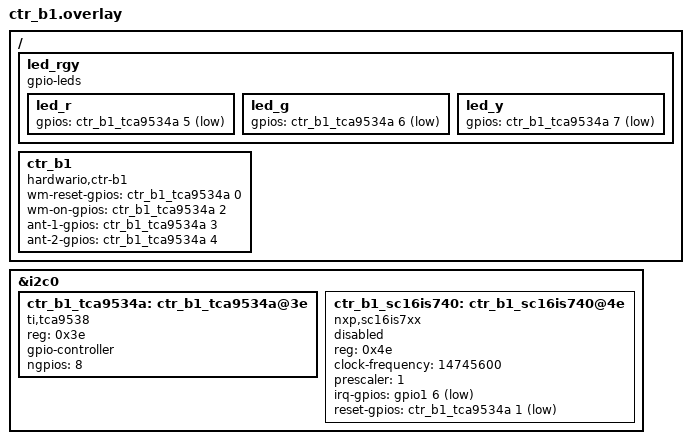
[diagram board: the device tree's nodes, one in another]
/*
 * Copyright (c) 2023 HARDWARIO a.s.
 *
 * SPDX-License-Identifier: LicenseRef-HARDWARIO-5-Clause
 */

/ {
	led_rgy {
		compatible = "gpio-leds";

		led_r: led_r {
			gpios = <&ctr_b1_tca9534a 5 GPIO_ACTIVE_LOW>;
		};

		led_g: led_g {
			gpios = <&ctr_b1_tca9534a 6 GPIO_ACTIVE_LOW>;
		};

		led_y: led_y {
			gpios = <&ctr_b1_tca9534a 7 GPIO_ACTIVE_LOW>;
		};
	};

	ctr_b1: ctr_b1 {
		compatible = "hardwario,ctr-b1";
		status = "okay";
		wm-reset-gpios = <&ctr_b1_tca9534a 0 GPIO_ACTIVE_HIGH>;
		wm-on-gpios = <&ctr_b1_tca9534a 2 GPIO_ACTIVE_HIGH>;
		ant-1-gpios = <&ctr_b1_tca9534a 3 GPIO_ACTIVE_HIGH>;
		ant-2-gpios = <&ctr_b1_tca9534a 4 GPIO_ACTIVE_HIGH>;
	};
};

&i2c0 {
	ctr_b1_tca9534a: ctr_b1_tca9534a@3e {
		compatible = "ti,tca9538";
		status = "okay";
		reg = <0x3e>;
		#gpio-cells = <2>;
		gpio-controller;
		ngpios = <8>;
	};

	ctr_b1_sc16is740: ctr_b1_sc16is740@4e {
		compatible = "nxp,sc16is7xx";
		status = "disabled";
		reg = <0x4e>;
		clock-frequency = <14745600>;
		prescaler = <1>;
		irq-gpios = <&gpio1 6 GPIO_ACTIVE_LOW>;
		reset-gpios = <&ctr_b1_tca9534a 1 GPIO_ACTIVE_LOW>;
	};
};
